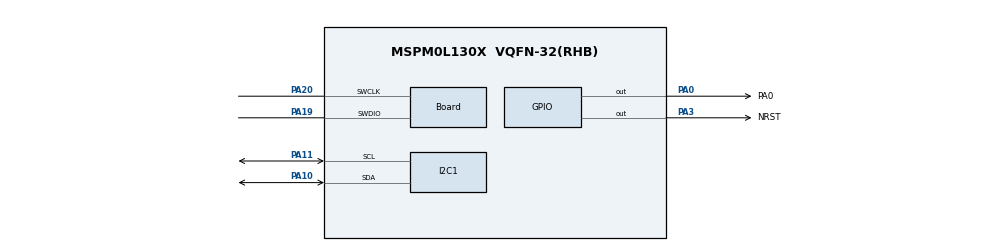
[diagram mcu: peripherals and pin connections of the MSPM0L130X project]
// @cliArgs --device "MSPM0L130X" --package "VQFN-32(RHB)" --part "Default"
// @cliArgs --board /ti/boards/LP_MSPM0L1306 --rtos nortos

/**
 * Import the modules used in this configuration.
 */
const Board = scripting.addModule("/ti/driverlib/Board");
const GPIO  = scripting.addModule("/ti/driverlib/GPIO", {}, false);
const GPIO1 = GPIO.addInstance();
const GPIO2 = GPIO.addInstance();
const GPIO3 = GPIO.addInstance();
const I2C   = scripting.addModule("/ti/driverlib/I2C", {}, false);
const I2C1  = I2C.addInstance();

/**
 * Write custom configuration values to the imported modules.
 */
Board.peripheral.$assign          = "DEBUGSS";
Board.peripheral.swclkPin.$assign = "PA20";
Board.peripheral.swdioPin.$assign = "PA19";

GPIO1.port                          = "PORTA";
GPIO1.$name                         = "GPIO_LED";
GPIO1.associatedPins.create(2);
GPIO1.associatedPins[0].$name       = "PA0";
GPIO1.associatedPins[0].assignedPin = "0";
GPIO1.associatedPins[0].pin.$assign = "PA0";
GPIO1.associatedPins[1].$name       = "Error";
GPIO1.associatedPins[1].assignedPin = "27";

GPIO2.$name                          = "GPIO_BSL";
GPIO2.associatedPins.create(2);
GPIO2.associatedPins[0].$name        = "NRST";
GPIO2.associatedPins[0].initialValue = "SET";
GPIO2.associatedPins[0].assignedPort = "PORTA";
GPIO2.associatedPins[0].assignedPin  = "3";
GPIO2.associatedPins[0].pin.$assign  = "PA3";
GPIO2.associatedPins[1].$name        = "Invoke";
GPIO2.associatedPins[1].assignedPort = "PORTA";
GPIO2.associatedPins[1].assignedPin  = "7";

GPIO3.$name                              = "GPIO_Button";
GPIO3.associatedPins[0].direction        = "INPUT";
GPIO3.associatedPins[0].internalResistor = "PULL_UP";
GPIO3.associatedPins[0].assignedPort     = "PORTA";
GPIO3.associatedPins[0].assignedPin      = "14";
GPIO3.associatedPins[0].$name            = "PIN_0";

I2C1.$name                     = "I2C_0";
I2C1.basicEnableController     = true;
I2C1.enableTimeoutA            = true;
I2C1.timeoutACount             = 255;
I2C1.peripheral.$assign        = "I2C0";
I2C1.peripheral.sdaPin.$assign = "PA10";
I2C1.peripheral.sclPin.$assign = "PA11";

const SYSCTL       = scripting.addModule("/ti/driverlib/SYSCTL", {}, false);
SYSCTL.clockTreeEn = true;
